# RS14100 register map
File version: 1.0
CPU: CM4 r0p1, little endian, MPU, FPU, 4 interrupt priority bits
Registers are 32-bit, read-write, reset 0x0 unless marked. A register's access mark holds for its fields unless they carry their own. Offsets are from the block's base; [hi:lo] are bit positions; {n}, {i} and the like mark numbered series; 'fields as' and 'values as' point back to an identical list.

## SIO — SERIAL GENERAL PERPOSE INPUT/OUTPUT
Base 0x47000000
0x00 ENABLE_REG — ENABLE REGISTER
  [15:0] SIO_OPERATION_ENABLE — Contains the Enables for all SIO
    0=Disable (SIO is disable); 1=Enable (SIO is enable)
0x04 PAUSE_REG — PAUSE REGISTER
  [15:0] SIO_POSITION_COUNTER_DISABLE — Contains sio position counter disable for all SIOs
    0=Disable (Counter in the corresponding SIO is enable); 1=Enable (Counter in the corresponding SIO is disable)
0x08 GPIO_IN_REG ro — GPIO Input Register
  [31:0] DATA — GPIO input pin status
0x0C GPIO_OUT_REG — GPIO Output Register
  [31:0] DATA — Value to be loaded on GPIO out pins
0x10 GPIO_OEN_REG reset 0xFFFF — GPIO Output enable Register
  [31:0] DATA — OEN for the GPIO pins
0x14 GPIO_INTR_EN_SET_REG — GPIO Interrupt Enable Set Register
  [15:0] INTR_ENABLE_SET — gpio interrupt enable set register for all SIOs
    0=Disable (Read as: interrupt is disabled Write as: No effect); 1=Enable (Read as: interrupt is enabled Write as:gpio interrupt enable gets set)
0x18 GPIO_INTR_EN_CLEAR_REG wo — GPIO Interrupt Enable Clear Register
  [15:0] INTR_ENABLE_CLEAR — gpio interrupt enable Clear register for all SIOs
    0=Disable (Read as: interrupt is disabled Write as: No effect); 1=Enable (Read as: interrupt is enabled Write as:gpio interrupt enable gets cleared)
0x1C GPIO_INTR_MASK_SET_REG reset 0xFFFF — GPIO Interrupt Enable Clear Register
  [15:0] INTR_MASK_SET — Common gpio interrupt mask set register for all SIOs
    0=Disable (Read as: interrupt is not present Write as: No effect); 1=Enable (Read as: interrupt mask is set Write as:gpio interrupt mask gets set)
0x20 GPIO_INTR_MASK_CLEAR_REG wo reset 0xFFFF — GPIO Interrupt Enable Clear Register
  [15:0] INTR_MASK_CLEAR — gpio interrupt mask clear register for all SIOs
    0=Disable (Read as: interrupt is not present Write as: No effect); 1=Enable (Read as: interrupt mask is set Write as:gpio interrupt mask gets cleared)
0x24 GPIO_INTR_STATUS_REG reset 0xFFFF — GPIO Interrupt Status Register
  [15:0] INTR_MASK_CLEAR wo — gpio interrupt mask clear register for all SIOs
    0=Disable (Read as: interrupt is not present Write as: No effect); 1=Enable (Read as: interrupt is present Write as:clears the corresponding bit)
{0x28+4i} SHIFT_COUNTER[{i}] (i=0..15) ro
  [13:0] SHIFT_COUNTER — shift counter current value
{0x68+4i} BUFFER_REG[{i}] (i=0..15) — Buffer Register
  [31:0] DATA — Data to load into the shift register
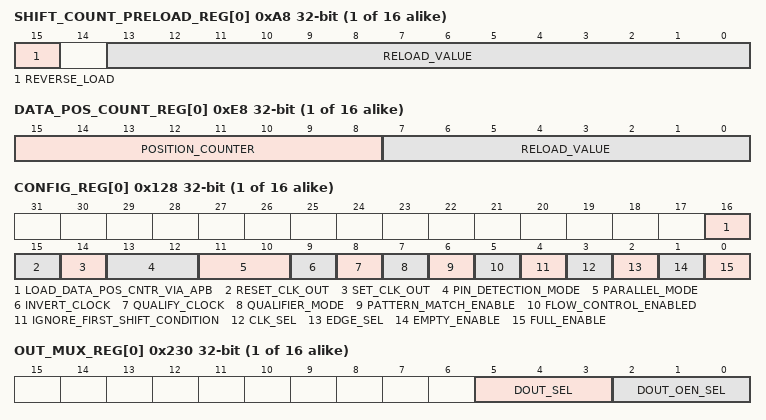
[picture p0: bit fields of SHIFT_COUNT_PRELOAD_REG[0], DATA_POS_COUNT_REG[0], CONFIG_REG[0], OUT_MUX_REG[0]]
{0xA8+4i} SHIFT_COUNT_PRELOAD_REG[{i}] (i=0..15) — Shift counter Reload Register
  [15] REVERSE_LOAD — When set, the data on APB is loaded to buffer is reverse order
  [13:0] RELOAD_VALUE — division factor required to generate shift clock
{0xE8+4i} DATA_POS_COUNT_REG[{i}] (i=0..15) — Data Position Counter Register
  [15:8] POSITION_COUNTER — The position counter can be loaded via AHB
  [7:0] RELOAD_VALUE — No. of shifts to happen before reloading the shift register with data/ pausing the operation
{0x128+4i} CONFIG_REG[{i}] (i=0..15) — Configuration Register
  [16] LOAD_DATA_POS_CNTR_VIA_APB — When set, data position counter can be loaded via APB
  [15] RESET_CLK_OUT — When high resets the sio clock_out port. This is used only when sio is not enabled
  [14] SET_CLK_OUT — When high sets the sio clock_out port. This is used only when sio is not enabled
  [13:12] PIN_DETECTION_MODE — Pin mode to be considered for gpio interrupt
    0=rise edge; 1=fall edge; 2=level zero; 3=level one
  [11:10] PARALLEL_MODE — No. of bits to shift/capture at valid clk edge
    0=1 bit; 1=2 bits; 2=4 bits; 3=8 bits
  [9] INVERT_CLOCK
    0=DIRECT (direct version of shift clock is provided out); 1=INVERTED (inverted version of the clock is provided out)
  [8] QUALIFY_CLOCK
    0=OUTPUT_QUALIFIED (output clock is not qualified); 1=OUTPUT_NOT_QUALIFIED (output clock is qualified with qualifier)
  [7] QUALIFIER_MODE
    0=DIRECT_QUALIFIER (Use direct qualifier input); 1=INVERTED_QUALIFIER (Use inverted qualifier)
  [6] PATTERN_MATCH_ENABLE — pattern match
    0=Disable (pattern match disable); 1=Enable (pattern match enable)
  [5] FLOW_CONTROL_ENABLED — flow control
    0=Disable (flow control disable); 1=Enable (flow control enable)
  [4] IGNORE_FIRST_SHIFT_CONDITION — data shift condition
    0=Disable (at a shift/capture happens at the first clock edge)
  [3] CLK_SEL — clock selection
    0=Disable (internal counter clock is used for shift operations and sent out); 1=Enable (external clock is used for shift operations and is sent out)
  [2] EDGE_SEL — edge selection
    0=Disable (pos edge); 1=Enable (neg edge)
  [1] EMPTY_ENABLE — When set, fifo full indication would be asserted when internal buffer is empty
  [0] FULL_ENABLE — When set, fifo full indication would be asserted when internal buffer is full
0x168 PATTERN_MATCH_MASK_REG_SLICE_0 — Pattern Match Mask Register 0
  [31:0] MATCH_MASK_LOWER16_BITS — Enable for lower 16 bits
    0=Disable (When bit is zero, it is considered as dont care); 1=Enable (When any bit is set, it is considered in pattern match)
0x16C PATTERN_MATCH_MASK_REG_slice_1 — Pattern Match Mask Register Slice 1
  fields as PATTERN_MATCH_MASK_REG_SLICE_0
0x170 PATTERN_MATCH_MASK_REG_SLICE_2 — Pattern Match Mask Register Slice 2
  fields as PATTERN_MATCH_MASK_REG_SLICE_0
{0x168+4i} PATTERN_MATCH_MASK_REG_SLICE_{i} (i=8..10) — Pattern Match Mask Register Slice {i}
  fields as PATTERN_MATCH_MASK_REG_SLICE_0
{0x1A8+4i} PATTERN_MATCH_REG_SLICE_{i} (i=0..2) — Pattern Match Mask Register Slice {i}
  [31:0] PATTERN_MATCH_LOWER16_BITS — Lower 16-bits of pattern to be detected
{0x1A8+4i} PATTERN_MATCH_REG_SLICE_{i} (i=8..10) — Pattern Match Mask Register Slice {i}
  [31:0] PATTERN_MATCH_LOWER16_BITS — Lower 16 bits of pattern to be detected
0x1F0 SHIFT_INTR_EN_SET_REG — Shift Interrupt Enable Set Register
  [15:0] INTR_ENABLE_SET — Common shift interrupt enable set register for all SIOs
    0=Disable (Read as: interrupt is disabled Write as: No effect); 1=Enable (Read as: interrupt is enabled Write as: shift interrupt enable gets set)
0x1F4 SHIFT_INTR_EN_CLEAR_REG wo — Shift Interrupt Enable Clear Register
  [15:0] INRT_ENABLE_CLEAR — Common shift interrupt enable Clear register for all SIOs
    0=Disable (Read as: interrupt is disabled Write as: No effect); 1=Enable (Read as: interrupt is enabled Write as: shift interrupt enable gets cleared)
0x1F8 SHIFT_INTR_MASK_SET_REG reset 0xFFFF — Shift Interrupt Mask Set Register
  [15:0] INRT_ENABLE_CLEAR — Common shift interrupt enable Set register for all SIOs
    0=Disable (Read as: interrupt mask is not present Write as: No effect); 1=Enable (Read as: interrupt mask is set Write as: shift interrupt mask gets set)
0x1FC SHIFT_INTR_MASK_CLEAR_REG wo reset 0xFFFF — Shift Interrupt Mask Clear Register
  [15:0] INTR_MASK_CLEAR — Common shift interrupt mask clear register for all SIOs
    0=Disable (Read as: interrupt mask is not present Write as: No effect); 1=Enable (Read as: interrupt mask is set Write as: shift interrupt mask gets cleared)
0x200 SHIFT_INTR_STATUS_REG — Shift Interrupt Status Register
  [15:0] INTR_ENABLE_SET — Common shift interrupt mask clear register for all SIOs
    0=Disable (Read as: interrupt is not present Write as: No effect); 1=Enable (Read as: interrupt is present Write as: clears the corresponding bit)
0x204 SWAP_INTR_EN_SET_REG — Swap Interrupt Enable Set Register
  [15:0] INTR_ENABLE_SET — Swap interrupt enable set register for all SIOs
    0=Disable (Read as: interrupt disable Write as: No effect); 1=Enable (Read as: interrupt is enabled Write as: swap interrupt enable gets set)
0x208 SWAP_INTR_EN_CLEAR_REG wo — Swap Interrupt Enable Clear Register
  [15:0] INTR_ENABLE_CLEAR — Swap interrupt enable Clear register for all SIOs
    0=Disable (Read as: interrupt is disable Write as: No effect); 1=Enable (Read as: interrupt is enabled Write as: swap interrupt enable gets Cleared)
0x20C SWAP_INTR_MASK_SET_REG reset 0xFFFF — Swap Interrupt Mask Set Register
  [15:0] INTR_MASK_SET — Common swap interrupt mask set register for all SIOs
    0=Disable (Read as: interrupt mask is not present Write as: No effect); 1=Enable (Read as: interrupt mask is set Write as: swap interrupt mask gets set)
0x210 SWAP_INTR_MASK_CLEAR_REG wo reset 0xFFFF — Swap Interrupt Mask Clear Register
  [15:0] INTR_MASK_CLEAR — Common swap interrupt mask Clear register for all SIOs
    0=Disable (Read as: interrupt mask is not present Write as: No effect); 1=Enable (Read as: interrupt mask is set Write as:swap interrupt mask gets cleared)
0x214 SWAP_INTR_STATUS_REG — Swap Interrupt Statusr Register
  [15:0] INTR_ENABLE_SET — Common swap interrupt status register for all SIOs
    0=Disable (Read as: interrupt mask is not present Write as: No effect); 1=Enable (Read as: interrupt is present Write as:clear the corresponding bit)
0x218 PATTERN_MATCH_INTR_EN_SET_REG — Pattern Match Interrupt Enable Set Register
  [15:0] INTR_ENABLE_SET — Common pattern or buffer under run interrupt enable set register for all SIOs. Each bit corresponds to one SIO
    0=Disable (Read as: No effect Write as: Interrupt disable); 1=Enable (Read as: Interrupt enable Write as: Interrupt enable)
0x21C PATTERN_MATCH_INTR_EN_CLEAR_REG wo — Pattern Match Interrupt Enable Clear Register
  [15:0] INRT_ENABLE_CLEAR — Common pattern or buffer under run interrupt enable clear register for all SIOs
    values as PATTERN_MATCH_INTR_EN_SET_REG.INTR_ENABLE_SET
0x220 PATTERN_MATCH_INTR_MASK_SET_REG reset 0xFFFF — Pattern Match Interrupt Mask Set Register
  [15:0] INTR_MASK_SET — Common pattern or buffer under run interrupt mask set register for all SIOs
    0=Disable (Read as: interrupt mask is not present Write as: No effect); 1=Enable (Read as: interrupt mask is set Write as: pattern interrupt mask gets set)
0x224 PATTERN_MATCH_INTR_MASK_CLEAR_REG wo reset 0xFFFF — Pattern Match Interrupt Mask Clear Register
  [15:0] INTR_MASK_CLEAR — Common pattern or buffer under run interrupt mask clear register for all SIOs
    0=Disable (Read as: interrupt mask is not present Write as: No effect); 1=Enable (Read as: interrupt mask is set Write as: pattern interrupt mask gets cleared)
0x228 PATTERN_MATCH_INTR_STATUS_REG — Pattern Match Interrupt Status Register
  [15:0] INTR_STATUS — Common pattern interrupt status register for all SIOs
    0=Disable (Read as: intr not present/not enabled Write as: No effect); 1=Enable (Read as: intr present Write as: clears the corresponding bit)
0x22C BUFFER_INTR_STATUS_REG — Buffer Interrupt Status Register
  fields as PATTERN_MATCH_INTR_STATUS_REG
{0x230+4i} OUT_MUX_REG[{i}] (i=0..15) — Output muxing Register
  [5:3] DOUT_SEL — Output mux select for GPIO pin 0
  [2:0] DOUT_OEN_SEL — OEN select for GPIO pin 0
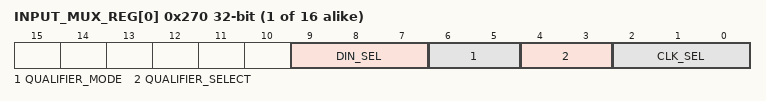
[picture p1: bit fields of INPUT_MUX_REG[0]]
{0x270+4i} INPUT_MUX_REG[{i}] (i=0..15) — Input muxing Register
  [9:7] DIN_SEL — Data in mux select
  [6:5] QUALIFIER_MODE
  [4:3] QUALIFIER_SELECT
  [2:0] CLK_SEL — Input clock select for SIO 0
